# UFS0_COMMON_0_P2A_WRAP_CFG_VBP_UFSHCI register map
Vendor: Texas Instruments
Peripheral module from a debugger description file (folder J7_AHP).
Registers are 32-bit, read-write, reset 0x0 unless marked. A register's access mark holds for its fields unless they carry their own. Offsets are as the file gives them; lines under a group give offsets from that group; [hi:lo] are bit positions; {n}, {i} and the like mark numbered series; 'fields as' and 'values as' point back to an identical list; <NAME> marks a mode.

## UFS0_COMMON_0_P2A_WRAP_CFG_VBP_UFSHCI (part 1 of 2)
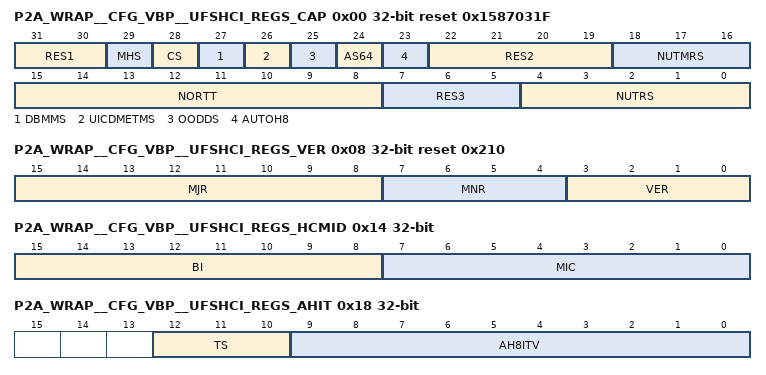
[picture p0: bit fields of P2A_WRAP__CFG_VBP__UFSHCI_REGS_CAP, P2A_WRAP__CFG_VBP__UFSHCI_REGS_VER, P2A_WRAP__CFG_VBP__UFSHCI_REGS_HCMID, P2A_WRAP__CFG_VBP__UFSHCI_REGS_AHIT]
0x00 P2A_WRAP__CFG_VBP__UFSHCI_REGS_CAP ro reset 0x1587031F
  [31:30] RES1 — RES - Reserved
  [29] MHS — MHS - Multi-Host Support Indicates that the host controller supports multi-host functionality.
  [28] CS — CS - Crypto Support Indicates that the host controller supports cryptographic operations.
  [27] DBMMS — DBMMS - Device Bus Master Mode supported [UM UFSHCI Only] Indicates whether the UFS host controller supports the device bus master mode, which is required to support the Unified Memory feature. The device bus master mode allows sending requests from the UFS device to the UFS host controller. The host controller responds to those requests.
  [26] UICDMETMS — UICDMETMS - UIC DME_TEST_MODE command supported Indicates whether the host controller supports the UniPro DME_TEST_MODE.req SAP primitive.
  [25] OODDS — OODDS - Out of order data delivery supported Indicates whether the host controller supports out of order data delivery for UTP data transfer. When set to 1, the host controller shall support of out of order data delivery from the target device. When set to 0, the host controller will not support out of order data delivery from the target device.
  [24] AS64 — 64AS - 64-bit addressing supported Indicates whether the host controller can access 64-bit data structures. When set to 1, the host controller shall make the 32-bit upper bits of the UTP Transfer Request List Base Address Upper 32-bit and UTP Task Management Request List Base Address Upper 32-bit, the PRD Base, and each PRD entry read/write. When cleared to 0, these are read-only and treated as 0 by the UFS Host Controller.
  [23] AUTOH8 — AUTOH8 - Auto-Hibernation Support Indicates whether the host controller support auto-hibernation: 0 - Host controller does not support auto-hibernation 1 - host controller does support auto hibernation
  [22:19] RES2 — RES - Reserved
  [18:16] NUTMRS — NUTMRS - Number of UTP Task Management Request Slots Zero-based value indicating the number of slots provided by the UTP Task Management Request List. A minimum of 1 and maximum of 8 slots may be supported.
  [15:8] NORTT — NORTT - Number of Pending RTTs supported Zero-based value indicating the maximum number of RTTs that can be pending on the host at a particular instance. RTTs will be processed in the same order as they were received [First-come-first-serve].
  [7:5] RES3 — RES - Reserved
  [4:0] NUTRS — NUTRS - Number of UTP Transfer Request Slots Zero-based value indicating the number of slots provided by the UTP Transfer Request List. A minimum of 1 and maximum of 32 slots may be supported.
0x08 P2A_WRAP__CFG_VBP__UFSHCI_REGS_VER ro reset 0x210
  [15:8] MJR — MJR - Major Version Number Indicates that the major version is 2.
  [7:4] MNR — MFR - Minor Version Number Indicates that the minor version is 0.
  [3:0] VER — VS - Version Suffix [VS] Version suffix in BCD format.
0x10 P2A_WRAP__CFG_VBP__UFSHCI_REGS_HCPID ro
  [31:0] PID — PID - Product ID Product ID that host controller manufacturer assigns for the host controller This is vendor specific.
0x14 P2A_WRAP__CFG_VBP__UFSHCI_REGS_HCMID ro
  [15:8] BI — BI - Bank Index This field contains an index value of the bank that contains the Manufacturer Identification Code. The BI value shall be equal to the number of the continuation fields that precede the MIC as specified by [JEDEC-JEP106].
  [7:0] MIC — MIC - Manufacturer Identification Code Manufacturer Identification code as defined by JEDEC in Standard Manufacturers identification code [JEDEC-JEP106].
0x18 P2A_WRAP__CFG_VBP__UFSHCI_REGS_AHIT
  [12:10] TS — TS - Time Scale 000 - Value times 1 us 001 - Value times 10 us 010 - Value times 100 us 011 - Value times 1 ms 100 - Value times 10 ms 101 - Value times 100 ms 110-111 - reserved
  [9:0] AH8ITV — AH8ITV - Auto-Hibernate Idle Timer Value This is the time that UFS subsystem must be idle before the UFS host controller may put the UFS link into HIBERN8 state autonomously. The idle timer value is multiplied by the indicated timer scale to yield an absolute timer value. The idle timer starts decrement when all of the following conditions are satisfied: - UTRLDBR = '0' - UTMRLDBR = '0' - No UIC commanding is outstanding The idle timer shall continue decrement until it reaches zero or it is stopped as result of software access to one of host controller interface registers. When idle timer changes a non-zero to zero, the host controller shall put the UFS link into HIBERN8 state. The host controller reloads this value each time the UFS link transitions out of the HIBERN8 state. Software writes 0 to disable Auto-Hibernate Idle Timer. Any non-zero value will enable Auto-Hibernate idle timer. Software access to any one of host controller interface registers shall automatically put UFS link out of HIBERN8 state.
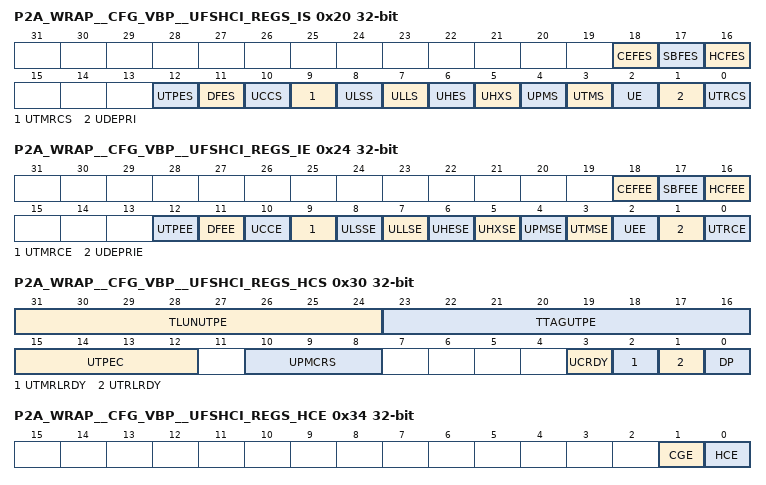
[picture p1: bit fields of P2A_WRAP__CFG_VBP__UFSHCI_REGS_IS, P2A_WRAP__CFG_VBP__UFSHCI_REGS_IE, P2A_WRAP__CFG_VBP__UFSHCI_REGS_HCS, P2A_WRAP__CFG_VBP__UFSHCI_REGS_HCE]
0x20 P2A_WRAP__CFG_VBP__UFSHCI_REGS_IS access not given
  [18] CEFES — CEFES - Crypto Engine Fatal Error Status Indicates that the host controller's encryption/decryption hardware has encountered an error from which it cannot recover. When the error occurs, the host controller is stopped and both UTRLRSR and UTMRLRSR will be cleared to '0' by host controller. (access R/W1TC)
  [17] SBFES — SBFES - System Bus Fatal Error Status Indicates that the host controller encountered a system bus error that it cannot recover from, such as a bad software pointer. When the error occurs, the host controller is stopped and both UTRRSR and UTMRRSR registers will be cleared to '0' by host controller. (access R/W1TC)
  [16] HCFES — HCFES - Host Controller Fatal Error Status Indicates that the host controller encountered a fatal error that it cannot recover from. When the error occurs, the host controller is stopped and both UTRRSR and UTMRRSR will be cleared to '0' by host controller. If the error occurs, host SW should reset the host controller. (access R/W1TC)
  [12] UTPES — UTPES - UTP Error Status Indicates that the host controller encountered an error at UTP layer that it cannot recover from. When the error occurs, the host controller will update UTP error code field within Host Controller Status register. It is up to host software to decide how to handle the error condition. (access R/W1TC)
  [11] DFES — DFES - Device Fatal Error Status Indicates that the host controller encountered a fatal error from device that it cannot recover. When the error occurs, the host controller is stopped and both UTRLRSR and UTMRLRSR will be cleared to '0' by host controller. If the error occurs, host SW should reset the host controller. (access R/W1TC)
  [10] UCCS — UCCS - UIC Command Completion Status This bit is set to '1' by the host controller upon completion of a UIC command. (access R/W1TC)
  [9] UTMRCS — UTMRCS - UTP Task Management Request Completion Status [UTMRCS]: This bit is set to '1' by the host controller upon completion of a task management function. (access R/W1TC)
  [8] ULSS — ULSS - UIC Link Startup Status Indication that Link start-up process has been initiated by the remote end of the Link. This bit corresponds to the UniPro DME_LINKSTARTUP.ind SAP primitive (access R/W1TC)
  [7] ULLS — ULLS - UIC Link Lost Status This indicates a condition where remote end is trying to re-establish a link and the link is lost. This bit corresponds to the UniPro DME_LINKLOST.ind SAP primitive. (access R/W1TC)
  [6] UHES — UHES - UIC Hibernate Enter Status Indicate that UniPro hibernate entering process has been completed and the Link state is changed to the Hibernate state if the process was successful. Register HCS.UPMCRS indicates if exit process was unsuccessful the failure. This bit corresponds to the UniPro DME_HIBERNATE_ENTER.ind SAP primitive. (access R/W1TC)
  [5] UHXS — UHXS - UIC Hibernate Exit Status Indicates that the Link has exited UniPro Hibernate state. Register HCS.UPMCRS indicates if exit process was unsuccessful the failure. This bit corresponds to the UniPro DME_HIBERNATE_EXIT.ind SAP primitive. (access R/W1TC)
  [4] UPMS — UPMS - UIC Power Mode Status Indicate that the UniPro/PA/DL part of the power mode change has been completed. Register HCS.UPMCRS contains the power mode change status. This bit corresponds to the UniPro DME_POWERMODE.ind SAP primitive. (access R/W1TC)
  [3] UTMS — UTMS - UIC Test Mode Status Indicate that the peer UniPro stack has been set to a given UniPro test mode. This bit corresponds to the UniProSM DME_TEST_MODE.ind SAP primitive. (access R/W1TC)
  [2] UE — UE - UIC Error Indicate that a layer in the UniPro stack has encountered an error condition. Register HCS.UEC contains the error code for the condition. This bit corresponds to the UniPro DME_ERROR.ind SAP primitive. This bit is asserted if at least one of the following bits is asserted: - UECPA.ERR - UECDL.ERR - UECN.ERR - UECT.ERR - UECDME.ERR (access R/W1TC)
  [1] UDEPRI — UDEPRI - UIC DME_ENDPOINTRESET Indication Indicate that the attached device has issued an DME_ENDPOINTRESET indication which is not allowed. (access R/W1TC)
  [0] UTRCS — UTRCS - UTP Transfer Request Completion Status This bit is set to '1' by the host controller upon one of the following: - Completion of a UTP transfer request with its UTRD Interrupt bit set to '1'. - Interrupt caused by the UTR interrupt aggregation logic. (access R/W1TC)
0x24 P2A_WRAP__CFG_VBP__UFSHCI_REGS_IE
  [18] CEFEE — CEFEE - Crypto Engine Fatal Error Enable When set and IS.CEFES is set, the controller shall generate an interrupt. This bit is functional only, if the crypto engine is implemented
  [17] SBFEE — SBFEE - System Bus Fatal Error Enable When set and IS.SBFES is set, the controller shall generate an interrupt.
  [16] HCFEE — HCFEE - Host Controller Fatal Error Enable When set and IS.HCFES is set, the controller shall generate an interrupt.
  [12] UTPEE — UTPEE - UTP Error Enable When set and IS.UTPES is set, the controller shall generate an interrupt
  [11] DFEE — DFEE - Device Fatal Error Enable When set and IS.DFES is set, the host controller shall generate an interrupt.
  [10] UCCE — UCCE - UIC COMMAND Completion Enable When set and IS.UCCS is set, the host controller shall generate an interrupt.
  [9] UTMRCE — UTMRCE - UTP Task Management Request Completion Enable When set and IS.UTMRCS is set, the host controller shall generate an interrupt.
  [8] ULSSE — ULSSE - UIC Link Startup Status Enable When set and IS.ULSS is set, the controller shall generate an interrupt.
  [7] ULLSE — ULLSE - UIC Link Lost Status Enable When set and IS.ULLS is set, the controller shall generate an interrupt.
  [6] UHESE — UHESE - UIC Hibernate Enter Status Enable When set and IS.UHES is set, the controller shall generate an interrupt.
  [5] UHXSE — UHXSE - UIC Hibernate Exit Status Enable When set and IS.UHXS is set, the controller shall generate an interrupt.
  [4] UPMSE — UPMSE - UIC Power Mode Status Enable When set and IS.UPMS is set, the controller shall generate an interrupt.
  [3] UTMSE — UTMSE - UIC Test Mode Status Enable When set and IS.UTMS is set, the controller shall generate an interrupt
  [2] UEE — UEE - UIC Error Enable When set and IS.UEE is set, the controller shall generate an interrupt.
  [1] UDEPRIE — UDEPRIE - UIC DME_ENDPOINTRESET When set and IS. UDEPRI is set, the controller shall generate an interrupt.
  [0] UTRCE — UTRCE - UTP Transfer Request Completion Enable When set and IS.UTRCS is set, the host controller shall generate an interrupt.
0x30 P2A_WRAP__CFG_VBP__UFSHCI_REGS_HCS ro
  [31:24] TLUNUTPE — TLUNUTPE - Target LUN of UTP error The LUN of the command that a UTP error occurs during execution of the command. This field is valid only when UTPES is set. It is automatically reset by the UFS Host Controller when UTPES is cleared.
  [23:16] TTAGUTPE — TTAGUTPE - Task Tag of UTP error The Task Tag of the command that a UTP error occurs during execution of the command. This field is valid only when UTPES is set. It is automatically reset by the UFS Host Controller when UTPES is cleared.
  [15:12] UTPEC — UTPEC - UTP Error Code Indicate that the error code of a UTP layer error. This field is valid only when UTPES is set. It is automatically reset by the UFS Host Controller when UTPES is cleared. 0h - Reserved 1h - Invalid Transaction Type 2h-Fh - Reserved
  [10:8] UPMCRS — UPMCRS - UIC Power Mode Change Request Status Indicate that the status of a UIC layer request for power mode change. Value Description: 0h: PWR_OK. The request was accepted. 1h: PWR_LOCAL. The local request was successfully applied. 2h: PWR_REMOTE. The remote request was successfully applied. Not used since this is associated to an UIC power mode change request from the UFS Device, which is not permitted. 3h: PWR_BUSY. The request was aborted due to concurrent requests. Not used since this is associated to an UIC power mode change request from the UFS Device, which is not permitted. 4h: PWR_ERROR_CAP. The request was rejected because the requested configuration exceeded the Link's capabilities. 5h: PWR_FATAL_ERROR. The request was aborted due to a communication problem. The Link may be inoperable. 6h-7h: Reserved.
  [3] UCRDY — UCRDY - UIC COMMAND Ready This field indicates whether the host controller is ready to process UIC COMMAND. Host software shall only set the UICCMD if HCS.UCRDY is set to '1'. This field is set to '1' if all of the following conditions are true: IS.DFES == 0 IS.HCFES == 0 No UIC command has been issued or the outstanding UIC command has been completed [HCS.UCCS == 1]. This field is cleared to 0 by host controller when one of the following conditions occur: IS.DFES == 1 IS.HCFES == 1 A write access to the UICCMD register
  [2] UTMRLRDY — UTMRLRDY - UTP Task Management Request List Ready This field is set to 1. if all of the following conditions are true: HCS.DP == 1 UTMRLDBR less than FFh IS.DFES == 0 IS.HCFES == 0 This field is cleared to 0. by host controller when one of the following conditions occur: HCS.DP == 0 UTMRLDBR == FFh IS.DFES == 1 IS.HCFES == 1 Host software shall only set the UTMRLRSR register if HCS.UTMRLRDY is set to '1'.
  [1] UTRLRDY — UTRLRDY - UTP Transfer Request List Ready This field is set to '1' if all of the following conditions are true: HCS.DP == 1 UTRLDBR less than FFFF_FFFFh IS.DFES == 0 IS.HCFES == 0 This field is cleared to '0' by host controller when one of the following conditions occur: HCS.DP == 0 UTRLDBR == FFFF_FFFFh IS.DFES == 1 IS.HCFES == 1 Host software shall only set the UTRLRSR bit to '1' if HCS. UTRLRDY is set to '1'.
  [0] DP — DP - Device Present This field is set to 1 when an UFS device is attached to the controller. This field is cleared to '0' when non-volatile memory is not attached to this controller. DP is set to 1 if the UIC layer is in the LinkUp power state.
0x34 P2A_WRAP__CFG_VBP__UFSHCI_REGS_HCE
  [1] CGE — Crypto General Enable Crypto General Enable: Enable/Disable bit for Crypto Engine. This bit is functional only, if the crypto engine is implemented. 1] bit value = 0 - Disable cryptographic operations for all transactions. 2] bit value = 1 - Enable cryptographic for transactions where UTRD.CE=1.
  [0] HCE — Host Controller Enable When set '1', host controller will autonomously go through the following initialization sequence: 1] Warm hardware reset of the UFS Host Controller 2] DME_RESET 3] DME_ENABLE The HCE bit stays 0 during the initialization sequence. In case the DME_ENABLE is not successful, HCE stays 0. If the initialization sequence is successful, HCE becomes 1. When HCE is cleared to 0, the UFS Host Controller is disabled and register values except for the 'Host Capabilities' register are volatile and may lose their content. If HCE is 1 and a 0 is written to the HCE register, the HCE bit stays 1 until all outstanding system bus read requests are completed.
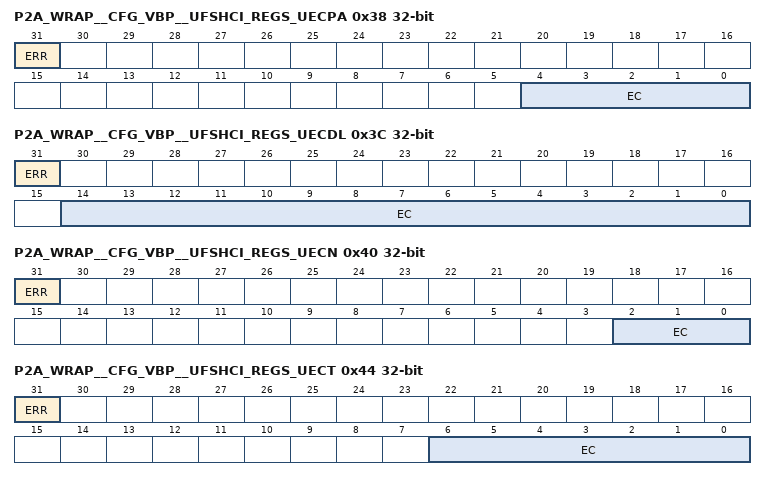
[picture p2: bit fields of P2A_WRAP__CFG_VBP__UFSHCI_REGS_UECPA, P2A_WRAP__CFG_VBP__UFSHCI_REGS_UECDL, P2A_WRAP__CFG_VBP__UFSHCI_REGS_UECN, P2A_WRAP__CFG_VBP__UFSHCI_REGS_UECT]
0x38 P2A_WRAP__CFG_VBP__UFSHCI_REGS_UECPA ro
  [31] ERR — ERR - UIC PHY Adapter Layer Error Indicates whether an error was generated by the PHY Adapter Layer.
  [4:0] EC — EC - UIC Adapter Layer Error Error code generated when IS.UE and UECPA.ERR are set to '1'. Bit Description: 00: PHY error on Lane 0 01: PHY error on Lane 1 [Fixed to 0 since only Lane 0 is supported] 02: PHY error on Lane 2 [Fixed to 0 since only Lane 0 is supported] 03: PHY error on Lane 3 [Fixed to 0 since only Lane 0 is supported] 04: Generic PHY Adapter error is flagged in case of a line reset that is either initiated by the local or peer device.
0x3C P2A_WRAP__CFG_VBP__UFSHCI_REGS_UECDL ro
  [31] ERR — ERR - UIC Data Link Layer Error Indicates whether an error was generated by the Data Link Layer.
  [14:0] EC — EC - UIC Data Link Layer Error Error code generated when IS.UE and UECDL.ERR are set to '1'. Reader is referred to UniPro Specification [UNIPRO] for the definition of the error codes. Bit Description: 00: NAC_RECEIVED 01: TCx_REPLAY_TIMER_EXPIRED 02: AFCx_REQUEST_TIMER_EXPIRED 03: FCx_PROTECTION_TIMER_EXPIRED 04: CRC_ERROR 05: RX_BUFFER_OVERFLOW 06: MAX_FRAME_LENGTH_EXCEEDED 07: WRONG_SEQUENCE_NUMBER 08: AFC_FRAME_SYNTAX_ERROR 09: NAC_FRAME_SYNTAX_ERROR 10: EOF_SYNTAX_ERROR 11: FRAME_SYNTAX_ERROR 12: BAD_CTRL_SYMBOL_TYPE 13: PA_INIT_ERROR 14: PA_ERROR_IND_RECEIVED
0x40 P2A_WRAP__CFG_VBP__UFSHCI_REGS_UECN ro
  [31] ERR — ERR - UIC Network Layer Error Indicates whether an error was generated by the Network Layer.
  [2:0] EC — EC - UIC Network Layer Error Code Error code generated when IS.UE and UECN.ERR are set to '1'. Reader is referred to UniPro Specification [UNIPRO] for the definition of the error codes. Bit Description: 00: UNSUPPORTED_HEADER_TYPE 01: BAD_DEVICEID_ENC 02: LHDR_TRAP_PACKET_DROPPING
0x44 P2A_WRAP__CFG_VBP__UFSHCI_REGS_UECT ro
  [31] ERR — ERR - UIC Transport Layer Error Indicates whether an error was generated by the Transport Layer.
  [6:0] EC — EC - UIC Transport Layer Error Code Error code generated when IS.UE and UECT.ERR are set to '1'. Reader is referred to UniPro Specification [UNIPRO] for the definition of the error codes. Bit Description: 00: UNSUPPORTED_HEADER_TYPE 01: UNKNOWN_CPORTID 02: NO_CONNECTION_RX 03: CONTROLLED_SEGMENT_DROPPING 04: BAD_TC 05: E2E_CREDIT_OVERFLOW 06: SAFETY_VALVE_DROPPING
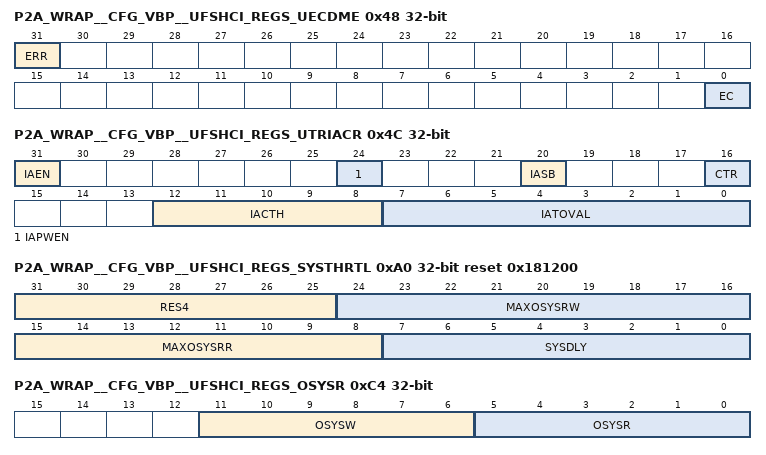
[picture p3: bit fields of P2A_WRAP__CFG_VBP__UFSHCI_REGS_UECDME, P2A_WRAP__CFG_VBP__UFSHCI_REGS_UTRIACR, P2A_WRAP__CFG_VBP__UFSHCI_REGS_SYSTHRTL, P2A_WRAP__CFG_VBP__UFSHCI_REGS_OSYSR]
0x48 P2A_WRAP__CFG_VBP__UFSHCI_REGS_UECDME ro
  [31] ERR — ERR - UIC DME Error Indicates whether an error was generated by the DME.
  [0] EC — EC - UIC DME Error Code Error code generated when IS.UE and UECDME.ERR are set to '1'. Bit Description: 00: Generic DME error
0x4C P2A_WRAP__CFG_VBP__UFSHCI_REGS_UTRIACR access per field
  [31] IAEN rw — IAEN - Interrupt Aggregation Enable/Disable When set to '0' by host software, command responses are not counted nor timed. Interrupts are still triggered by responses where the interrupt bit is set in the UTRD. When set to '1', the interrupt aggregation mechanism is enabled and aggregation-based interrupts are generated.
  [24] IAPWEN rw — IAPWEN - Interrupt aggregation parameter write enable When host SW writes '1', the values in IACTH and IATOVAL are updated with the contents written at the same cycle. When host SW writes 0, the values in IACTH and IATOVAL are not updated. Note: Write operations to IACTH and IATOVAL are only allowed when no commands are outstanding.
  [20] IASB ro — IASB - Interrupt aggregation status bit This bit indicates to Host SW whether any responses have been received and counted towards interrupt aggregation [i.e. IASB is set if IA counter greater than 0]. Bit Value Description: 0: No commands has been received since last counter reset [IA counter == 0] 1: At least one command has been received and counted [IA counter greater than 0]
  [16] CTR wo — CTR - Counter and Timer Reset When host SW writes '1', the interrupt aggregation timer and counter are reset. It is recommended that host software use this field to reset the timer and counter every time it services newly received UTP responses.
  [12:8] IACTH rw — IACTH - Interrupt aggregation counter threshold Host SW uses this field to configure the number of responses that are required to generate an interrupt. As UTP responses are received by the host controller, they are counted. When the count reaches the value configured in this field, an interrupt is generated [IS.UTRCS bit is set]. The maximum allowed value is 31. Note: When IACTH is 0, responses are not counted, and counting-based interrupts are not generated. In order to write to this field, the IAPWEN bit must be set at the same write operation.
  [7:0] IATOVAL rw — IATOVAL - Interrupt aggregation timeout value Host SW uses this field to configure the maximum time allowed between a response arrival to the host controller and the generation of an interrupt. Timer Operation: The timer is reset by software during the interrupt service routine. It starts running when the host controller receives the first response to a Regular Command, after the timer was reset. The timer stops when it reaches the value configured in IATOVAL field, and IS.UTRCS bit is set. Note: When IATOVAL is 0, the timer is not running, and timer-based interrupts are not generated. The Time units in this field are 40 us. Therefore, writing 0x01 represents a time-out value of 40 us, and writing 0xFF represents a time-out value of 10.2 ms
0x50 P2A_WRAP__CFG_VBP__UFSHCI_REGS_UTRLBA
  [31:10] UTRLBA — UTRLBA - UTP Transfer Request List Base Address Indicates the 32-bit base physical address for the UTP Transfer Request list. This base is used when fetching commands for execution. The structure pointed to by this address range is 1KB in length. This address shall be 1KB aligned as indicated by bits 9:0 being read only.
0x54 P2A_WRAP__CFG_VBP__UFSHCI_REGS_UTRLBAU
  [31:0] UTRLBAU — UTRLBAU - UTP Transfer Request List Base Address Upper Indicates the upper 32-bits for the UTP Transfer Request list base physical address. This base is used when fetching commands for execution.
0x58 P2A_WRAP__CFG_VBP__UFSHCI_REGS_UTRLDBR access not given
  [31:0] UTRLDBR — UTRLDBR - UTP Transfer Request List Door bell Register This field is bit significant. Each bit corresponds to a slot in the UTP Transfer Request List, where bit 0 corresponds to request slot 0. A bit in this field is set to '1' by host software to indicate to the host controller that a transfer request has been built in system memory for the associated transfer request slot and may be ready for execution. The host software indicates no change to request slots by setting the associated bits in this field to '0'. Bits in this field shall only be set '1' or '0' by host software when UTRLRSR is set to '1'. When a transfer request is completed [with success or error], the corresponding bit is cleared to '0' by the host controller. The host controller always process transfer requests in-order according to the order submitted to the list. In case of multiple commands with single door bell register ringing [batch mode], The dispatch order for these transfer requests by host controller will base on their index in the List. A transfer request with lower index value will be executed before a transfer request with higher index value. This field is also cleared when UTRLRSR is written from a '1' to a '0' by host software. (access R/W1TS)
0x5C P2A_WRAP__CFG_VBP__UFSHCI_REGS_UTRLCLR wo
  [31:0] UTRLCLR — UTRLCLR - UTP Transfer Request List CLear Register This field is bit significant. Each bit corresponds to a slot in the UTP Transfer Request List, where bit 0 corresponds to request slot 0. A bit in this field is set to '0' by host software to indicate to the host controller that a transfer request slot is cleared. The host controller shall free up any resources associated to the request slot immediately, and shall set the associated bit in UTRLDBR to '0'. The host software indicates no change to request slots by setting the associated bits in this field to '1'. Bits in this field shall only be set '1' or '0' by host software when UTRLRSR is set to '1'. The host software shall use this field only when a UTP Transfer Request is expected to not be completed, e.g., when a Transfer Request was aborted, or in case of a system bus error, such as an invalid UTRD.
0x60 P2A_WRAP__CFG_VBP__UFSHCI_REGS_UTRLRSR
  [0] UTRLRSR — UTRLRSR - UTP Transfer Request List Run-Stop Register When set to '1', the host controller may process the list. Host controller starts processing the list at entry '0'. The host controller continues process the list as long as this bit is set to a '1'. When cleared to '0', the host controller shall continue to complete all the outstanding transfer requests in the list and then stop. This bit shall only be set to '1' when HCS.UTRLRDY is set to '1'.
0x64 P2A_WRAP__CFG_VBP__UFSHCI_REGS_UTRLCNR access not given
  [31:0] UTRLCNR — UTRLCNR - UTP Transfer Request List Completion Notification Register This field is bit significant. Each bit corresponds to a slot in the UTP Transfer Request List, where bit 0 corresponds to request slot 0. A bit in this field is set to '1' by the host controller when a transfer request from the associated transfer request slot has completed [with success or error]. The host controller sets the bit at the same time it clears the bit with the same index in UTRLDBR. Host software is expected to clear the bit, by writing '1' to it, after processing the completed task. Clearing a bit in this register shall have no effect on the hardware, other than changing the value of this register. The host controller shall clear this register when UTRLRSR is written from a '0' to a '1' by host software. (access R/W1TC)
0x70 P2A_WRAP__CFG_VBP__UFSHCI_REGS_UTMRLBA
  [31:10] UTMRLBA — UTMRLBA - UTP Task Management Request List Base Address Indicates the 32-bit base physical address for the list. This base is used when fetching Task Management Functions for execution. The structure pointed to by this address range is 1KB in length. This address shall be 1KB aligned as indicated by bits 9:0 being read only.
0x74 P2A_WRAP__CFG_VBP__UFSHCI_REGS_UTMRLBAU
  [31:0] UTMRLBAU — UTMRLBAU - UTP Task Management Request List Base Address Indicates the upper 32-bits for the list base physical address. This base is used when fetching task management functions for execution.
0x78 P2A_WRAP__CFG_VBP__UFSHCI_REGS_UTMRLDBR access not given
  [7:0] UTMRLDBR — UTMRLDBR - UTP Task Management Request List Doorbell Register This field is bit significant. Each bit corresponds to a task management request slot in the List, where bit 0 corresponds to T slot 0. This field is set by host software to indicate to the host controller that a task management request has been built in system memory and may be ready for execution. When a task management request is completed [with success or error], the corresponding bit is cleared to '0' by the host controller. Bits in this field shall only be set to '1' by host software when UTMRLRSR is set to '1'. The host controller always process task management request in-order according to the order submitted to the list. In case of multiple requests with single door bell register ringing [batch mode], The dispatch order for these requests by host controller will base on their index in the List. A task management with lower index value will be executed before a task management request with higher index value. This field is also cleared when UTMRLRSR is written from a '1' to a '0' by host software. (access R/W1TS)
0x7C P2A_WRAP__CFG_VBP__UFSHCI_REGS_UTMRLCLR wo
  [7:0] UTMRLCLR — UTMRLCLR - UTP Task Management List CLear Register This field is bit significant. Each bit corresponds to a slot in the task management request List, where bit 0 corresponds to slot 0. A bit in this field is set to '0' by host software to indicate to the host controller that a task management request slot is cleared. The host controller shall free up any resources associated to the task management request slot immediately, and shall set the associated bit in UTMRLDBR to '0'. The host software indicates no change to task management request slots by setting the associated bits in this field to '1'. Bits in this field shall only be set '1' or '0' by host software when UTRLRSR is set to '1'. The host software shall use this field only when a UTP Task Management Request is expected to not be completed, e.g., in case of a system bus error, such as an invalid UTMRD.
0x80 P2A_WRAP__CFG_VBP__UFSHCI_REGS_UTMRLRSR
  [0] UTMRLRSR — UTMRLRSR - UTP Task Management Request List Run-Stop Register When set to '1', the host controller may process the list. Host controller starts processing the list at entry '0'. The host controller continues process the list as long as this bit is set to a '1'. When cleared to '0', the host controller shall continue to complete all the outstanding task management requests in the list and then stop. This bit shall only be set to '1' when HCS.UTMRLRDY is set to '1'.
0x90 P2A_WRAP__CFG_VBP__UFSHCI_REGS_UICCMD
  [7:0] CMDOP — CMDOP - Command Opcode Indicate the Opcode of a UIC Command to be dispatched to local UIC layer. When this register is set, the host controller shall take the values of UICCMDARGx as the corresponding parameters [input and output] that are a part of the UIC Command. Opcode UIC Command Configuration: 01h: DME_GET 02h: DME_SET 03h: DME_PEER_GET 04h: DME_PEER_SET 05h-0Fh: Reserved Control: 10h-11h: Reserved 12h: DME_ENABLE [Not permitted] 13h: Reserved 14h: DME_RESET 15h: DME_ENDPOINTRESET 16h: DME_LINKSTARTUP 17h: DME_HIBERNATE_ENTER 18h: DME_HIBERNATE_EXIT 19h-FFh: Reserved 19h-FFh: Reserved
0x94 P2A_WRAP__CFG_VBP__UFSHCI_REGS_UICCMDARG1
  [31:0] ARG1 — ARG1 - UIC Command Argument 1: MIBattribute, GenSelectorIndex, ResetLevel This contains the value for the 1st argument of the UIC command if applicable. The content of this field varies with the UIC Command [UICCMD]. UIC cmd = DME_GET: Bit[31:24] = MIBattribute Bit[23:16] = MIBattribute Bit[15:08] = GenSelectorIndex Bit[07:00] = GenSelectorIndex UIC cmd = DME_SET: Bit[31:24] = MIBattribute Bit[23:16] = MIBattribute Bit[15:08] = GenSelectorIndex Bit[07:00] = GenSelectorIndex UIC cmd = DME_PEER_GET: Bit[31:24] = MIBattribute Bit[23:16] = MIBattribute Bit[15:08] = GenSelectorIndex Bit[07:00] = GenSelectorIndex UIC cmd = DME_PEER_SET: Bit[31:24] = MIBattribute Bit[23:16] = MIBattribute Bit[15:08] = GenSelectorIndex Bit[07:00] = GenSelectorIndex UIC cmd = DME_POWERON: Bit[31:00] = Reserved UIC cmd = DME_POWEROFF: Bit[31:00] = Reserved UIC cmd = DME_ENABLE: Bit[31:00] = Reserved UIC cmd = DME_RESET: Bit[31:24] = Reserved Bit[23:16] = Reserved Bit[15:08] = Reserved Bit[07:00] = ResetLevel UIC cmd = DME_ENDPOINTRESET: Bit[31:00] = Reserved UIC cmd = DME_LINKSTARTUP: Bit[31:00] = Reserved UIC cmd = DME_HIBERNATE_ENTER: Bit[31:00] = Reserved UIC cmd = DME_HIBERNATE_EXIT: Bit[31:00] = Reserved UIC cmd = DME_TEST_MODE: Bit[31:00] = Reserved
0x98 P2A_WRAP__CFG_VBP__UFSHCI_REGS_UICCMDARG2
  [31:0] ARG2 — ARG2 - UIC Command Argument 2: AttrSetType, ConfigResultCode, GenericErrorCode This register contains the value for the 2nd argument of the UIC command if applicable. The content of this field vary with UIC Command. UIC Command = DME_GET: Bit[07:00] = ConfigResultCode UIC Command = DME_SET: Bit[07:00] = ConfigResultCode UIC Command = DME_PEER_GET: Bit[07:00] = ConfigResultCode UIC Command = DME_PEER_SET: Bit[07:00] = ConfigResultCode UIC Command = DME_POWERON: Bit[07:00] = GenericErrorCode UIC Command = DME_POWEROFF: Bit[07:00] = GenericErrorCode UIC Command = DME_ENABLE: Bit[07:00] = GenericErrorCode UIC Command = DME_RESET: Bit[07:00] = Reserved UIC Command = DME_ENDPOINTRESET: Bit[07:00] = GenericErrorCode UIC Command = DME_LINKSTARTUP: Bit[07:00] = GenericErrorCode UIC Command = DME_HIBERNATE_ENTER: Bit[07:00] = GenericErrorCode UIC Command = DME_HIBERNATE_EXIT: Bit[07:00] = GenericErrorCode UIC Command = DME_TEST_MODE: Bit[07:00] = GenericErrorCode
0x9C P2A_WRAP__CFG_VBP__UFSHCI_REGS_UICCMDARG3
  [31:0] ARG3 — ARG3 - Argument 3 This register contains the value for the 3rd argument of the UIC command if applicable. The content of this field vary with UIC Command. UIC Command = DME_GET: Bit[31:00] = MIBvalue_R UIC Command = DME_SET: Bit[31:00] = MIBvalue_W UIC Command = DME_PEER_GET: Bit[31:00] = MIBvalue_R UIC Command = DME_PEER_SET: Bit[31:00] = MIBvalue_W UIC Command = DME_POWERON: Bit[31:00] = Reserved UIC Command = DME_POWEROFF: Bit[31:00] = Reserved UIC Command = DME_ENABLE: Bit[31:00] = Reserved UIC Command = DME_RESET: Bit[31:00] = Reserved UIC Command = DME_ENDPOINTRESET: Bit[31:00] = Reserved UIC Command = DME_LINKSTARTUP: Bit[31:00] = Reserved UIC Command = DME_HIBERNATE_ENTER: Bit[31:00] = Reserved UIC Command = DME_HIBERNATE_EXIT: Bit[31:00] = Reserved UIC Command = DME_TEST_MODE: Bit[31:00] = Reserved
0xA0 P2A_WRAP__CFG_VBP__UFSHCI_REGS_SYSTHRTL access per field reset 0x181200
  [31:25] RES4 ro — RES - Reserved
  [24:16] MAXOSYSRW rw — MAXOSYSRW - Max Outstanding SYS Write Requests [AXI Only] Actual limit of outstanding SYS write requests. This register value shall not be higher than specified by the P_P_RDP_MAX_OUTSTANDING parameter. Writing of illegal values is not checked or prohibited by the hardware. The default value is defined by the P_P_RDP_MAX_OUTSTANDING parameter, so that the Software knows the maximum allowed value by reading this register. 0x0 - no limitation 0xF - 15 outstanding requests
  [15:8] MAXOSYSRR rw — MAXOSYSRR - Max Outstanding SYS Read Requests Actual limit of outstanding SYS read requests. This register value shall not be higher than specified by the P_P_WDP_MAX_OUTSTANDING parameter. Writing of illegal values is not checked or prohibited by the hardware. The default value is defined by the P_P_WDP_MAX_OUTSTANDING parameter, so that the Software knows the maximum allowed value by reading this register. 0x0 - no limitation 0xF - 15 outstanding requests Note: For the IP with the OCP bus interface, this register defines the total number of outstanding request read and writes combined.
  [7:0] SYSDLY rw — SYSDLY - SYS Delay This register defines the minimum delay in HClk cycles between two system bus accesses. The register defines the delay for both, read and write channel.
0xAC P2A_WRAP__CFG_VBP__UFSHCI_REGS_HCI_MMIO_TOSH_UNIRESPOL
  [0] RESPOL — RESPOL - UniPro Reset Polling 0: Wait for power on ResetCnf pulse 1: Skip polling of ResetCnf When the UFSHCI come out of reset, the HCI will wait for LA_ResetCnf and then the UFSHCI enable request can be forwarded. At this point the Host Controller will wait again for LA_ResetCnf. Having this bit set to '1' will allow to skip the first waiting period. The default value of this register depends from the P_P_RESPOL_1B parameter.
0xC4 P2A_WRAP__CFG_VBP__UFSHCI_REGS_OSYSR ro
  [11:6] OSYSW — OSYSW - Outstanding SYS Write Requests This register gives the number of outstanding SYS write requests. In case the System Host writes a 0 to the HCE register, the UFS Host Controller stays enabled [HCE=0] until all outstanding SYS write requests are completed, means OSYSW=0.
  [5:0] OSYSR — OSYSR - Outstanding SYS Read Requests This register gives the number of outstanding SYS read requests. In case the System Host writes a 0 to the HCE register, the UFS Host Controller stays enabled [HCE=0] until all outstanding SYS read requests are completed, means OSYSR=0. This register can be used to detect system bus problems. In case the system does not correctly return to 0, the system bus may hang.
